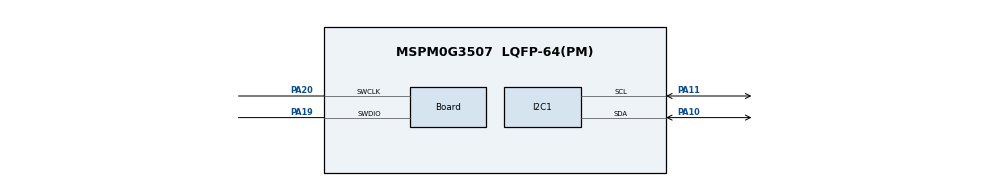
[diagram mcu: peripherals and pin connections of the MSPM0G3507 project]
//@cliArgs --device "MSPM0G350X" --package "LQFP-64(PM)" --part "Default"
//@v2CliArgs --device "MSPM0G3507" --package "LQFP-64(PM)"
// @cliArgs --board /ti/boards/LP_MSPM0G3507 --rtos nortos

/**
 * Import the modules used in this configuration.
 */
const Board         = scripting.addModule("/ti/driverlib/Board");
const GPIO          = scripting.addModule("/ti/driverlib/GPIO", {}, false);
const GPIO1         = GPIO.addInstance();
const I2C           = scripting.addModule("/ti/driverlib/I2C", {}, false);
const I2C1          = I2C.addInstance();
const SYSCTL        = scripting.addModule("/ti/driverlib/SYSCTL");
const ProjectConfig = scripting.addModule("/ti/project_config/ProjectConfig");

/**
 * Write custom configuration values to the imported modules.
 */
Board.peripheral.$assign          = "DEBUGSS";
Board.peripheral.swclkPin.$assign = "PA20";
Board.peripheral.swdioPin.$assign = "PA19";

GPIO1.$name                          = "GPIO_GRP_0";
GPIO1.associatedPins.create(9);
GPIO1.associatedPins[0].$name        = "PIN_0";
GPIO1.associatedPins[0].assignedPort = "PORTA";
GPIO1.associatedPins[0].direction    = "INPUT";
GPIO1.associatedPins[0].polarity     = "RISE_FALL";
GPIO1.associatedPins[0].interruptEn  = true;
GPIO1.associatedPins[0].assignedPin  = "25";
GPIO1.associatedPins[1].$name        = "PIN_1";
GPIO1.associatedPins[1].direction    = "INPUT";
GPIO1.associatedPins[1].assignedPort = "PORTA";
GPIO1.associatedPins[1].polarity     = "RISE_FALL";
GPIO1.associatedPins[1].interruptEn  = true;
GPIO1.associatedPins[1].assignedPin  = "8";
GPIO1.associatedPins[2].$name        = "PIN_2";
GPIO1.associatedPins[2].assignedPort = "PORTA";
GPIO1.associatedPins[2].direction    = "INPUT";
GPIO1.associatedPins[2].polarity     = "RISE_FALL";
GPIO1.associatedPins[2].interruptEn  = true;
GPIO1.associatedPins[2].assignedPin  = "22";
GPIO1.associatedPins[3].$name        = "PIN_3";
GPIO1.associatedPins[3].assignedPort = "PORTA";
GPIO1.associatedPins[3].direction    = "INPUT";
GPIO1.associatedPins[3].polarity     = "RISE_FALL";
GPIO1.associatedPins[3].interruptEn  = true;
GPIO1.associatedPins[3].assignedPin  = "26";
GPIO1.associatedPins[4].$name        = "PIN_4";
GPIO1.associatedPins[4].assignedPort = "PORTA";
GPIO1.associatedPins[4].direction    = "INPUT";
GPIO1.associatedPins[4].polarity     = "RISE_FALL";
GPIO1.associatedPins[4].interruptEn  = true;
GPIO1.associatedPins[4].assignedPin  = "24";
GPIO1.associatedPins[5].$name        = "PIN_5";
GPIO1.associatedPins[5].assignedPort = "PORTA";
GPIO1.associatedPins[5].direction    = "INPUT";
GPIO1.associatedPins[5].polarity     = "RISE_FALL";
GPIO1.associatedPins[5].interruptEn  = true;
GPIO1.associatedPins[5].assignedPin  = "27";
GPIO1.associatedPins[6].$name        = "PIN_6";
GPIO1.associatedPins[6].assignedPort = "PORTA";
GPIO1.associatedPins[6].direction    = "INPUT";
GPIO1.associatedPins[6].polarity     = "RISE_FALL";
GPIO1.associatedPins[6].interruptEn  = true;
GPIO1.associatedPins[6].assignedPin  = "18";
GPIO1.associatedPins[7].$name        = "PIN_7";
GPIO1.associatedPins[7].direction    = "INPUT";
GPIO1.associatedPins[7].polarity     = "RISE_FALL";
GPIO1.associatedPins[7].interruptEn  = true;
GPIO1.associatedPins[7].assignedPort = "PORTA";
GPIO1.associatedPins[7].assignedPin  = "0";
GPIO1.associatedPins[8].$name        = "IRQ_OUT";
GPIO1.associatedPins[8].initialValue = "SET";
GPIO1.associatedPins[8].assignedPort = "PORTA";
GPIO1.associatedPins[8].assignedPin  = "12";

I2C1.$name                             = "I2C";
I2C1.basicControllerBusSpeed           = 400000;
I2C1.advControllerTXFIFOTRIG           = "BYTES_1";
I2C1.advTargetTXFIFOTRIG               = "BYTES_1";
I2C1.basicTargetAddress                = 0x48;
I2C1.basicEnableTarget                 = true;
I2C1.advAnalogGlitchFilter             = "DISABLED";
I2C1.intTarget                         = ["RXFIFO_TRIGGER","START","STOP","TXFIFO_EMPTY","TX_DONE"];
I2C1.peripheral.$assign                = "I2C0";
I2C1.peripheral.sdaPin.$assign         = "PA10";
I2C1.peripheral.sclPin.$assign         = "PA11";

SYSCTL.clockTreeEn = true;

ProjectConfig.migrationCondition = true;
